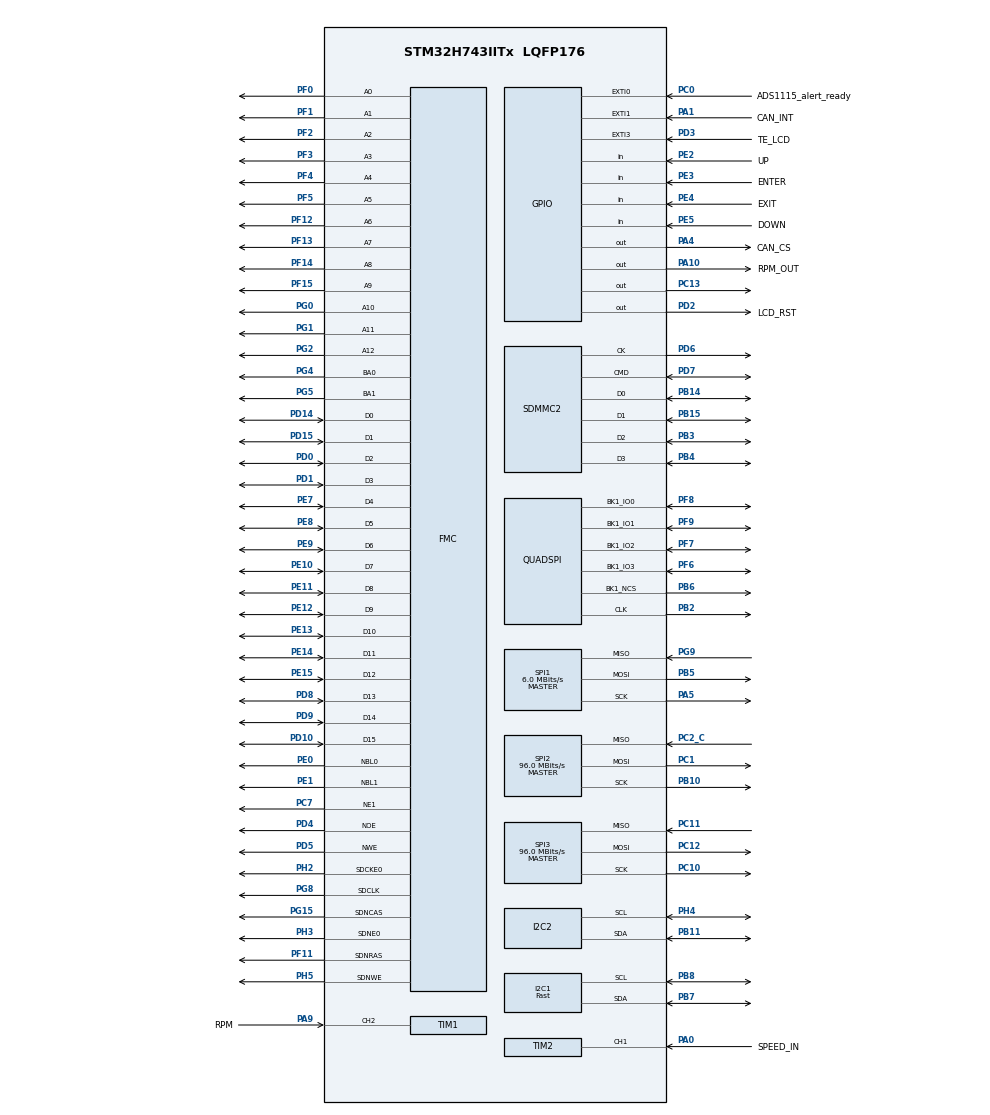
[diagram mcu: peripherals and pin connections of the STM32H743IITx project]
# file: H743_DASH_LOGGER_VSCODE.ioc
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CORTEX_M7.AccessPermission_S-Cortex_Memory_Protection_Unit_Region1_Settings_S=MPU_REGION_FULL_ACCESS
CORTEX_M7.AccessPermission_S-Cortex_Memory_Protection_Unit_Region2_Settings_S=MPU_REGION_FULL_ACCESS
CORTEX_M7.AccessPermission_S-Cortex_Memory_Protection_Unit_Region3_Settings_S=MPU_REGION_FULL_ACCESS
CORTEX_M7.AccessPermission_Spec=MPU_REGION_FULL_ACCESS
CORTEX_M7.BaseAddress_S-Cortex_Memory_Protection_Unit_Region1_Settings_S=0x90000000
CORTEX_M7.BaseAddress_S-Cortex_Memory_Protection_Unit_Region2_Settings_S=0xc0000000
CORTEX_M7.BaseAddress_S-Cortex_Memory_Protection_Unit_Region3_Settings_S=0x90000000
CORTEX_M7.BaseAddress_Spec=0x60000000
CORTEX_M7.CPU_DCache=Enabled
CORTEX_M7.CPU_ICache=Enabled
CORTEX_M7.DisableExec_S-Cortex_Memory_Protection_Unit_Region1_Settings_S=MPU_INSTRUCTION_ACCESS_DISABLE
CORTEX_M7.DisableExec_S-Cortex_Memory_Protection_Unit_Region2_Settings_S=MPU_INSTRUCTION_ACCESS_DISABLE
CORTEX_M7.DisableExec_Spec=MPU_INSTRUCTION_ACCESS_DISABLE
CORTEX_M7.Enable_S-Cortex_Memory_Protection_Unit_Region1_Settings_S=MPU_REGION_ENABLE
CORTEX_M7.Enable_S-Cortex_Memory_Protection_Unit_Region2_Settings_S=MPU_REGION_ENABLE
CORTEX_M7.Enable_S-Cortex_Memory_Protection_Unit_Region3_Settings_S=MPU_REGION_ENABLE
CORTEX_M7.IsBufferable_S-Cortex_Memory_Protection_Unit_Region1_Settings_S=MPU_ACCESS_BUFFERABLE
CORTEX_M7.IsBufferable_S-Cortex_Memory_Protection_Unit_Region2_Settings_S=MPU_ACCESS_NOT_BUFFERABLE
CORTEX_M7.IsBufferable_S-Cortex_Memory_Protection_Unit_Region3_Settings_S=MPU_ACCESS_BUFFERABLE
CORTEX_M7.IsBufferable_Spec=MPU_ACCESS_NOT_BUFFERABLE
CORTEX_M7.IsCacheable_S-Cortex_Memory_Protection_Unit_Region1_Settings_S=MPU_ACCESS_CACHEABLE
CORTEX_M7.IsCacheable_S-Cortex_Memory_Protection_Unit_Region2_Settings_S=MPU_ACCESS_NOT_CACHEABLE
CORTEX_M7.IsCacheable_S-Cortex_Memory_Protection_Unit_Region3_Settings_S=MPU_ACCESS_CACHEABLE
CORTEX_M7.IsCacheable_Spec=MPU_ACCESS_NOT_CACHEABLE
CORTEX_M7.IsShareable_S-Cortex_Memory_Protection_Unit_Region2_Settings_S=MPU_ACCESS_NOT_SHAREABLE
CORTEX_M7.IsShareable_Spec=MPU_ACCESS_NOT_SHAREABLE
CORTEX_M7.MPU_Control=MPU_PRIVILEGED_DEFAULT
CORTEX_M7.Size_S-Cortex_Memory_Protection_Unit_Region1_Settings_S=MPU_REGION_SIZE_16MB
CORTEX_M7.Size_S-Cortex_Memory_Protection_Unit_Region2_Settings_S=MPU_REGION_SIZE_32MB
CORTEX_M7.Size_S-Cortex_Memory_Protection_Unit_Region3_Settings_S=MPU_REGION_SIZE_1MB
CORTEX_M7.Size_Spec=MPU_REGION_SIZE_512KB
CORTEX_M7.SubRegionDisable_S-Cortex_Memory_Protection_Unit_Region2_Settings_S=0x00
CORTEX_M7.SubRegionDisable_Spec=0
CORTEX_M7.TypeExtField_S-Cortex_Memory_Protection_Unit_Region2_Settings_S=MPU_TEX_LEVEL1
CORTEX_M7.TypeExtField_Spec=MPU_TEX_LEVEL0
CORTEX_M7.default_mode_Activation=1
Dma.MEMTOMEM.0.Direction=DMA_MEMORY_TO_MEMORY
Dma.MEMTOMEM.0.EventEnable=DISABLE
Dma.MEMTOMEM.0.FIFOMode=DMA_FIFOMODE_ENABLE
Dma.MEMTOMEM.0.FIFOThreshold=DMA_FIFO_THRESHOLD_FULL
Dma.MEMTOMEM.0.Instance=DMA2_Stream0
Dma.MEMTOMEM.0.MemBurst=DMA_MBURST_SINGLE
Dma.MEMTOMEM.0.MemDataAlignment=DMA_MDATAALIGN_HALFWORD
Dma.MEMTOMEM.0.MemInc=DMA_MINC_DISABLE
Dma.MEMTOMEM.0.Mode=DMA_NORMAL
Dma.MEMTOMEM.0.PeriphBurst=DMA_PBURST_SINGLE
Dma.MEMTOMEM.0.PeriphDataAlignment=DMA_PDATAALIGN_HALFWORD
Dma.MEMTOMEM.0.PeriphInc=DMA_PINC_ENABLE
Dma.MEMTOMEM.0.Polarity=HAL_DMAMUX_REQ_GEN_RISING
Dma.MEMTOMEM.0.Priority=DMA_PRIORITY_HIGH
Dma.MEMTOMEM.0.RequestNumber=1
Dma.MEMTOMEM.0.SignalID=NONE
Dma.MEMTOMEM.0.SyncEnable=DISABLE
Dma.MEMTOMEM.0.SyncPolarity=HAL_DMAMUX_SYNC_NO_EVENT
Dma.MEMTOMEM.0.SyncRequestNumber=1
Dma.MEMTOMEM.0.SyncSignalID=NONE
Dma.Request0=MEMTOMEM
FMC.AddressHoldTime1=8
FMC.AddressSetupTime1=8
FMC.BusTurnAroundDuration1=4
FMC.CASLatency1=FMC_SDRAM_CAS_LATENCY_3
FMC.ColumnBitsNumber1=FMC_SDRAM_COLUMN_BITS_NUM_9
FMC.DataSetupTime1=40
FMC.ExitSelfRefreshDelay1=8
FMC.ExtendedMode1=FMC_EXTENDED_MODE_DISABLE
FMC.LoadToActiveDelay1=3
FMC.RCDDelay1=3
FMC.RPDelay1=3
FMC.RPDelay2=3
FMC.ReadBurst1=FMC_SDRAM_RBURST_DISABLE
FMC.ReadPipeDelay1=FMC_SDRAM_RPIPE_DELAY_1
FMC.ReadPipeDelay2=FMC_SDRAM_RPIPE_DELAY_2
FMC.RowCycleDelay1=8
FMC.RowCycleDelay2=8
FMC.SDClockPeriod1=FMC_SDRAM_CLOCK_PERIOD_3
FMC.SDClockPeriod2=FMC_SDRAM_CLOCK_PERIOD_3
FMC.SelfRefreshTime1=5
FMC.WriteFifo1=FMC_WRITE_FIFO_DISABLE
FMC.WriteRecoveryTime1=4
I2C1.I2C_Speed_Mode=I2C_Fast
I2C1.NoStretchMode=I2C_NOSTRETCH_DISABLE
I2C1.Timing=0x00B03FDB
I2C2.Timing=0x307075B1
Mcu.Family=STM32H7
Mcu.Name=STM32H743IITx
Mcu.Package=LQFP176
Mdma.MDMA_Channel0.Request0=SW
Mdma.MDMA_Channel0.RequestsNb=1
Mdma.MDMA_Channel0.SW.0.BlockCount=0
Mdma.MDMA_Channel0.SW.0.BlockDataLength=0
Mdma.MDMA_Channel0.SW.0.BufferTransferLength=32
Mdma.MDMA_Channel0.SW.0.CircularMode=MDMA_LINEAR_LIST
Mdma.MDMA_Channel0.SW.0.DataAlignment=MDMA_DATAALIGN_RIGHT
Mdma.MDMA_Channel0.SW.0.DestBlockAddressOffset=0
Mdma.MDMA_Channel0.SW.0.DestBurst=MDMA_DEST_BURST_SINGLE
Mdma.MDMA_Channel0.SW.0.DestDataSize=MDMA_DEST_DATASIZE_HALFWORD
Mdma.MDMA_Channel0.SW.0.DestinationInc=MDMA_DEST_INC_DISABLE
Mdma.MDMA_Channel0.SW.0.DstAddress=0
Mdma.MDMA_Channel0.SW.0.Endianness=MDMA_LITTLE_ENDIANNESS_PRESERVE
Mdma.MDMA_Channel0.SW.0.Instance=MDMA_Channel0
Mdma.MDMA_Channel0.SW.0.MaskAddress=0
Mdma.MDMA_Channel0.SW.0.MaskData=0
Mdma.MDMA_Channel0.SW.0.Priority=MDMA_PRIORITY_HIGH
Mdma.MDMA_Channel0.SW.0.Rank=First
Mdma.MDMA_Channel0.SW.0.SourceBlockAddressOffset=0
Mdma.MDMA_Channel0.SW.0.SourceBurst=MDMA_SOURCE_BURST_SINGLE
Mdma.MDMA_Channel0.SW.0.SourceDataSize=MDMA_SRC_DATASIZE_HALFWORD
Mdma.MDMA_Channel0.SW.0.SourceInc=MDMA_SRC_INC_HALFWORD
Mdma.MDMA_Channel0.SW.0.SrcAddress=0
Mdma.MDMA_Channel0.SW.0.TransferTriggerMode=MDMA_BLOCK_TRANSFER
Mdma.RequestSet0=MDMA_Channel0
Mdma.RequestSetsNb=1
NVIC.EXTI0_IRQn=true\:5\:0\:true\:false\:true\:true\:true\:true
NVIC.EXTI1_IRQn=true\:5\:0\:true\:false\:true\:true\:true\:true
NVIC.EXTI3_IRQn=true\:5\:0\:false\:false\:true\:true\:true\:true
NVIC.FMC_IRQn=true\:0\:0\:false\:false\:true\:true\:true\:true
NVIC.I2C1_ER_IRQn=true\:0\:0\:false\:false\:true\:true\:true\:true
NVIC.I2C1_EV_IRQn=true\:0\:0\:false\:false\:true\:true\:true\:true
NVIC.MDMA_IRQn=true\:0\:0\:false\:false\:true\:false\:true\:true
NVIC.PriorityGroup=NVIC_PRIORITYGROUP_4
NVIC.RCC_IRQn=true\:5\:0\:true\:false\:true\:true\:false\:true
NVIC.SDMMC2_IRQn=true\:0\:0\:false\:false\:true\:true\:true\:true
NVIC.TIM1_CC_IRQn=true\:0\:0\:false\:false\:true\:true\:true\:true
NVIC.TIM2_IRQn=true\:0\:0\:false\:false\:true\:true\:true\:true
NVIC.TIM6_DAC_IRQn=true\:5\:0\:true\:false\:true\:true\:true\:true
PA0.GPIO_Label=SPEED_IN
PA0.Signal=S_TIM2_CH1_ETR
PA1.GPIO_Label=CAN_INT
PA1.GPIO_ModeDefaultEXTI=GPIO_MODE_IT_FALLING
PA1.Signal=GPXTI1
PA10.GPIO_Label=RPM_OUT
PA10.Signal=GPIO_Output
PA13\ (JTMS/SWDIO).Mode=Serial_Wire
PA13\ (JTMS/SWDIO).Signal=DEBUG_JTMS-SWDIO
PA14\ (JTCK/SWCLK).Mode=Serial_Wire
PA14\ (JTCK/SWCLK).Signal=DEBUG_JTCK-SWCLK
PA4.GPIO_Label=CAN_CS
PA4.GPIO_Speed=GPIO_SPEED_FREQ_VERY_HIGH
PA4.PinState=GPIO_PIN_SET
PA4.Signal=GPIO_Output
PA5.GPIO_Speed=GPIO_SPEED_FREQ_VERY_HIGH
PA5.Mode=Full_Duplex_Master
PA5.Signal=SPI1_SCK
PA9.GPIO_Label=RPM
PA9.GPIO_PuPd=GPIO_PULLDOWN
PA9.GPIO_Speed=GPIO_SPEED_FREQ_MEDIUM
PA9.Signal=S_TIM1_CH2
PB10.Mode=Full_Duplex_Master
PB10.Signal=SPI2_SCK
PB11.Mode=I2C
PB11.Signal=I2C2_SDA
PB14.Mode=SD_4_bits_Wide_bus
PB14.Signal=SDMMC2_D0
PB15.Mode=SD_4_bits_Wide_bus
PB15.Signal=SDMMC2_D1
PB2.GPIO_Speed=GPIO_SPEED_FREQ_VERY_HIGH
PB2.Mode=Single Bank 1
PB2.Signal=QUADSPI_CLK
PB3\ (JTDO/TRACESWO).Mode=SD_4_bits_Wide_bus
PB3\ (JTDO/TRACESWO).Signal=SDMMC2_D2
PB4\ (NJTRST).Mode=SD_4_bits_Wide_bus
PB4\ (NJTRST).Signal=SDMMC2_D3
PB5.GPIO_Speed=GPIO_SPEED_FREQ_VERY_HIGH
PB5.Mode=Full_Duplex_Master
PB5.Signal=SPI1_MOSI
PB6.GPIO_Speed=GPIO_SPEED_FREQ_VERY_HIGH
PB6.Mode=Single Bank 1
PB6.Signal=QUADSPI_BK1_NCS
PB7.GPIO_Speed=GPIO_SPEED_FREQ_VERY_HIGH
PB7.Mode=I2C
PB7.Signal=I2C1_SDA
PB8.GPIO_Speed=GPIO_SPEED_FREQ_VERY_HIGH
PB8.Mode=I2C
PB8.Signal=I2C1_SCL
PC0.GPIO_Label=ADS1115_alert_ready
PC0.GPIO_ModeDefaultEXTI=GPIO_MODE_IT_FALLING
PC0.GPIO_PuPd=GPIO_PULLUP
PC0.Signal=GPXTI0
PC1.Mode=Full_Duplex_Master
PC1.Signal=SPI2_MOSI
PC10.Mode=Full_Duplex_Master
PC10.Signal=SPI3_SCK
PC11.Mode=Full_Duplex_Master
PC11.Signal=SPI3_MISO
PC12.Mode=Full_Duplex_Master
PC12.Signal=SPI3_MOSI
PC13.Signal=GPIO_Output
PC14-OSC32_IN\ (OSC32_IN).Mode=LSE-External-Oscillator
PC14-OSC32_IN\ (OSC32_IN).Signal=RCC_OSC32_IN
PC15-OSC32_OUT\ (OSC32_OUT).Mode=LSE-External-Oscillator
PC15-OSC32_OUT\ (OSC32_OUT).Signal=RCC_OSC32_OUT
PC2_C.Mode=Full_Duplex_Master
PC2_C.Signal=SPI2_MISO
PC7.GPIO_Speed_High_Default=GPIO_SPEED_FREQ_VERY_HIGH
PC7.Mode=NorPsramChipSelect1_1
PC7.Signal=FMC_NE1
PD0.GPIO_Speed_High_Default=GPIO_SPEED_FREQ_VERY_HIGH
PD0.Signal=FMC_D2_DA2
PD1.GPIO_Speed_High_Default=GPIO_SPEED_FREQ_VERY_HIGH
PD1.Signal=FMC_D3_DA3
PD10.GPIO_Speed_High_Default=GPIO_SPEED_FREQ_VERY_HIGH
PD10.Signal=FMC_D15_DA15
PD14.GPIO_Speed_High_Default=GPIO_SPEED_FREQ_VERY_HIGH
PD14.Signal=FMC_D0_DA0
PD15.GPIO_Speed_High_Default=GPIO_SPEED_FREQ_VERY_HIGH
PD15.Signal=FMC_D1_DA1
PD2.GPIO_Label=LCD_RST
PD2.GPIO_Speed=GPIO_SPEED_FREQ_VERY_HIGH
PD2.Signal=GPIO_Output
PD3.GPIO_Label=TE_LCD
PD3.GPIO_ModeDefaultEXTI=GPIO_MODE_IT_RISING
PD3.GPIO_PuPd=GPIO_PULLDOWN
PD3.Signal=GPXTI3
PD4.GPIO_Speed_High_Default=GPIO_SPEED_FREQ_VERY_HIGH
PD4.Signal=FMC_NOE
PD5.GPIO_Speed_High_Default=GPIO_SPEED_FREQ_VERY_HIGH
PD5.Signal=FMC_NWE
PD6.Mode=SD_4_bits_Wide_bus
PD6.Signal=SDMMC2_CK
PD7.Mode=SD_4_bits_Wide_bus
PD7.Signal=SDMMC2_CMD
PD8.GPIO_Speed_High_Default=GPIO_SPEED_FREQ_VERY_HIGH
PD8.Signal=FMC_D13_DA13
PD9.GPIO_Speed_High_Default=GPIO_SPEED_FREQ_VERY_HIGH
PD9.Signal=FMC_D14_DA14
PE0.GPIO_Speed_High_Default=GPIO_SPEED_FREQ_VERY_HIGH
PE0.Signal=FMC_NBL0
PE1.GPIO_Speed_High_Default=GPIO_SPEED_FREQ_VERY_HIGH
PE1.Signal=FMC_NBL1
PE10.GPIO_Speed_High_Default=GPIO_SPEED_FREQ_VERY_HIGH
PE10.Signal=FMC_D7_DA7
PE11.GPIO_Speed_High_Default=GPIO_SPEED_FREQ_VERY_HIGH
PE11.Signal=FMC_D8_DA8
PE12.GPIO_Speed_High_Default=GPIO_SPEED_FREQ_VERY_HIGH
PE12.Signal=FMC_D9_DA9
PE13.GPIO_Speed_High_Default=GPIO_SPEED_FREQ_VERY_HIGH
PE13.Signal=FMC_D10_DA10
PE14.GPIO_Speed_High_Default=GPIO_SPEED_FREQ_VERY_HIGH
PE14.Signal=FMC_D11_DA11
PE15.GPIO_Speed_High_Default=GPIO_SPEED_FREQ_VERY_HIGH
PE15.Signal=FMC_D12_DA12
PE2.GPIO_Label=UP
PE2.GPIO_Mode=GPIO_MODE_INPUT
PE2.GPIO_PuPd=GPIO_PULLUP
PE2.Signal=GPIO_Input
PE3.GPIO_Label=ENTER
PE3.GPIO_Mode=GPIO_MODE_INPUT
PE3.GPIO_PuPd=GPIO_PULLUP
PE3.Signal=GPIO_Input
PE4.GPIO_Label=EXIT
PE4.GPIO_Mode=GPIO_MODE_INPUT
PE4.GPIO_PuPd=GPIO_PULLUP
PE4.Signal=GPIO_Input
PE5.GPIO_Label=DOWN
PE5.GPIO_Mode=GPIO_MODE_INPUT
PE5.GPIO_PuPd=GPIO_PULLUP
PE5.Signal=GPIO_Input
PE7.GPIO_Speed_High_Default=GPIO_SPEED_FREQ_VERY_HIGH
PE7.Signal=FMC_D4_DA4
PE8.GPIO_Speed_High_Default=GPIO_SPEED_FREQ_VERY_HIGH
PE8.Signal=FMC_D5_DA5
PE9.GPIO_Speed_High_Default=GPIO_SPEED_FREQ_VERY_HIGH
PE9.Signal=FMC_D6_DA6
PF0.GPIO_Speed_High_Default=GPIO_SPEED_FREQ_VERY_HIGH
PF0.Signal=FMC_A0
PF1.GPIO_Speed_High_Default=GPIO_SPEED_FREQ_VERY_HIGH
PF1.Signal=FMC_A1
PF11.GPIO_Speed_High_Default=GPIO_SPEED_FREQ_VERY_HIGH
PF11.Signal=FMC_SDNRAS
PF12.GPIO_Speed_High_Default=GPIO_SPEED_FREQ_VERY_HIGH
PF12.Signal=FMC_A6
PF13.GPIO_Speed_High_Default=GPIO_SPEED_FREQ_VERY_HIGH
PF13.Signal=FMC_A7
PF14.GPIO_Speed_High_Default=GPIO_SPEED_FREQ_VERY_HIGH
PF14.Signal=FMC_A8
PF15.GPIO_Speed_High_Default=GPIO_SPEED_FREQ_VERY_HIGH
PF15.Signal=FMC_A9
PF2.GPIO_Speed_High_Default=GPIO_SPEED_FREQ_VERY_HIGH
PF2.Signal=FMC_A2
PF3.GPIO_Speed_High_Default=GPIO_SPEED_FREQ_VERY_HIGH
PF3.Signal=FMC_A3
PF4.GPIO_Speed_High_Default=GPIO_SPEED_FREQ_VERY_HIGH
PF4.Signal=FMC_A4
PF5.GPIO_Speed_High_Default=GPIO_SPEED_FREQ_VERY_HIGH
PF5.Signal=FMC_A5
PF6.GPIO_Speed=GPIO_SPEED_FREQ_VERY_HIGH
PF6.Mode=Single Bank 1
PF6.Signal=QUADSPI_BK1_IO3
PF7.GPIO_Speed=GPIO_SPEED_FREQ_VERY_HIGH
PF7.Mode=Single Bank 1
PF7.Signal=QUADSPI_BK1_IO2
PF8.GPIO_Speed=GPIO_SPEED_FREQ_VERY_HIGH
PF8.Mode=Single Bank 1
PF8.Signal=QUADSPI_BK1_IO0
PF9.GPIO_Speed=GPIO_SPEED_FREQ_VERY_HIGH
PF9.Mode=Single Bank 1
PF9.Signal=QUADSPI_BK1_IO1
PG0.GPIO_Speed_High_Default=GPIO_SPEED_FREQ_VERY_HIGH
PG0.Signal=FMC_A10
PG1.GPIO_Speed_High_Default=GPIO_SPEED_FREQ_VERY_HIGH
PG1.Signal=FMC_A11
PG15.GPIO_Speed_High_Default=GPIO_SPEED_FREQ_VERY_HIGH
PG15.Signal=FMC_SDNCAS
PG2.GPIO_Speed_High_Default=GPIO_SPEED_FREQ_VERY_HIGH
PG2.Signal=FMC_A12
PG4.GPIO_Speed_High_Default=GPIO_SPEED_FREQ_VERY_HIGH
PG4.Signal=FMC_A14_BA0
PG5.GPIO_Speed_High_Default=GPIO_SPEED_FREQ_VERY_HIGH
PG5.Signal=FMC_A15_BA1
PG8.GPIO_Speed_High_Default=GPIO_SPEED_FREQ_VERY_HIGH
PG8.Signal=FMC_SDCLK
PG9.GPIO_Speed=GPIO_SPEED_FREQ_VERY_HIGH
PG9.Mode=Full_Duplex_Master
PG9.Signal=SPI1_MISO
PH0-OSC_IN\ (PH0).Mode=HSE-External-Oscillator
PH0-OSC_IN\ (PH0).Signal=RCC_OSC_IN
PH1-OSC_OUT\ (PH1).Mode=HSE-External-Oscillator
PH1-OSC_OUT\ (PH1).Signal=RCC_OSC_OUT
PH2.GPIO_Speed_High_Default=GPIO_SPEED_FREQ_VERY_HIGH
PH2.Mode=SdramChipSelect1_1
PH2.Signal=FMC_SDCKE0
PH3.GPIO_Speed_High_Default=GPIO_SPEED_FREQ_VERY_HIGH
PH3.Mode=SdramChipSelect1_1
PH3.Signal=FMC_SDNE0
PH4.Mode=I2C
PH4.Signal=I2C2_SCL
PH5.GPIO_Speed_High_Default=GPIO_SPEED_FREQ_VERY_HIGH
PH5.Signal=FMC_SDNWE
ProjectManager.HeapSize=0x200
ProjectManager.StackSize=0x400
ProjectManager.TargetToolchain=CMake
QUADSPI.ChipSelectHighTime=QSPI_CS_HIGH_TIME_2_CYCLE
QUADSPI.ClockPrescaler=2
QUADSPI.FifoThreshold=1
QUADSPI.FlashSize=23
QUADSPI.SampleShifting=QSPI_SAMPLE_SHIFTING_HALFCYCLE
RCC.ADCFreq_Value=56000000
RCC.APB1Freq_Value=120000000
RCC.APB2Freq_Value=120000000
RCC.APB3Freq_Value=120000000
RCC.APB4Freq_Value=120000000
RCC.CortexFreq_Value=480000000
RCC.D1PPRE=RCC_APB3_DIV2
RCC.D2PPRE1=RCC_APB1_DIV2
RCC.D2PPRE2=RCC_APB2_DIV2
RCC.D3PPRE=RCC_APB4_DIV2
RCC.DIVM1=4
RCC.DIVM2=4
RCC.DIVN1=60
RCC.DIVN2=14
RCC.DIVP2=4
RCC.DIVQ1=5
RCC.DIVQ2=4
RCC.FMCCLockSelection=RCC_FMCCLKSOURCE_PLL2
RCC.HCLKFreq_Value=240000000
RCC.HPRE=RCC_HCLK_DIV2
RCC.PLL2FRACN=0
RCC.PLL3FRACN=0
RCC.PLLFRACN=0
RCC.ProductRev=revV
RCC.SYSCLKFreq_VALUE=480000000
RCC.SYSCLKSource=RCC_SYSCLKSOURCE_PLLCLK
RCC.SupplySource=PWR_LDO_SUPPLY
RCC.USART16CLockSelection=RCC_USART16CLKSOURCE_HSI
RCC.USBFreq_Value=192000000
SDMMC2.ClockDiv=23
SH.FMC_A0.0=FMC_A0,A0_1
SH.FMC_A0.1=FMC_A0,13b-sda1
SH.FMC_A1.0=FMC_A1,13b-sda1
SH.FMC_A10.0=FMC_A10,13b-sda1
SH.FMC_A11.0=FMC_A11,13b-sda1
SH.FMC_A12.0=FMC_A12,13b-sda1
SH.FMC_A14_BA0.0=FMC_BA0,FourSdramBanks1
SH.FMC_A15_BA1.0=FMC_BA1,FourSdramBanks1
SH.FMC_A2.0=FMC_A2,13b-sda1
SH.FMC_A3.0=FMC_A3,13b-sda1
SH.FMC_A4.0=FMC_A4,13b-sda1
SH.FMC_A5.0=FMC_A5,13b-sda1
SH.FMC_A6.0=FMC_A6,13b-sda1
SH.FMC_A7.0=FMC_A7,13b-sda1
SH.FMC_A8.0=FMC_A8,13b-sda1
SH.FMC_A9.0=FMC_A9,13b-sda1
SH.FMC_D0_DA0.0=FMC_D0,16b-d1
SH.FMC_D0_DA0.1=FMC_D0,sd-16b-d1
SH.FMC_D10_DA10.0=FMC_D10,16b-d1
SH.FMC_D10_DA10.1=FMC_D10,sd-16b-d1
SH.FMC_D11_DA11.0=FMC_D11,16b-d1
SH.FMC_D11_DA11.1=FMC_D11,sd-16b-d1
SH.FMC_D12_DA12.0=FMC_D12,16b-d1
SH.FMC_D12_DA12.1=FMC_D12,sd-16b-d1
SH.FMC_D13_DA13.0=FMC_D13,16b-d1
SH.FMC_D13_DA13.1=FMC_D13,sd-16b-d1
SH.FMC_D14_DA14.0=FMC_D14,16b-d1
SH.FMC_D14_DA14.1=FMC_D14,sd-16b-d1
SH.FMC_D15_DA15.0=FMC_D15,16b-d1
SH.FMC_D15_DA15.1=FMC_D15,sd-16b-d1
SH.FMC_D1_DA1.0=FMC_D1,16b-d1
SH.FMC_D1_DA1.1=FMC_D1,sd-16b-d1
SH.FMC_D2_DA2.0=FMC_D2,16b-d1
SH.FMC_D2_DA2.1=FMC_D2,sd-16b-d1
SH.FMC_D3_DA3.0=FMC_D3,16b-d1
SH.FMC_D3_DA3.1=FMC_D3,sd-16b-d1
SH.FMC_D4_DA4.0=FMC_D4,16b-d1
SH.FMC_D4_DA4.1=FMC_D4,sd-16b-d1
SH.FMC_D5_DA5.0=FMC_D5,16b-d1
SH.FMC_D5_DA5.1=FMC_D5,sd-16b-d1
SH.FMC_D6_DA6.0=FMC_D6,16b-d1
SH.FMC_D6_DA6.1=FMC_D6,sd-16b-d1
SH.FMC_D7_DA7.0=FMC_D7,16b-d1
SH.FMC_D7_DA7.1=FMC_D7,sd-16b-d1
SH.FMC_D8_DA8.0=FMC_D8,16b-d1
SH.FMC_D8_DA8.1=FMC_D8,sd-16b-d1
SH.FMC_D9_DA9.0=FMC_D9,16b-d1
SH.FMC_D9_DA9.1=FMC_D9,sd-16b-d1
SH.FMC_NBL0.0=FMC_NBL0,Sd2ByteEnable1
SH.FMC_NBL1.0=FMC_NBL1,Sd2ByteEnable1
SH.FMC_NOE.0=FMC_NOE,Lcd1
SH.FMC_NWE.0=FMC_NWE,Lcd1
SH.FMC_SDCLK.0=FMC_SDCLK,13b-sda1
SH.FMC_SDNCAS.0=FMC_SDNCAS,13b-sda1
SH.FMC_SDNRAS.0=FMC_SDNRAS,13b-sda1
SH.FMC_SDNWE.0=FMC_SDNWE,13b-sda1
SH.S_TIM1_CH2.0=TIM1_CH2,PWM_Input_2
SH.S_TIM2_CH1_ETR.0=TIM2_CH1,PWM_Input_1
SPI1.BaudRatePrescaler=SPI_BAUDRATEPRESCALER_32
SPI1.CalculateBaudRate=6.0 MBits/s
SPI1.DataSize=SPI_DATASIZE_8BIT
SPI1.Direction=SPI_DIRECTION_2LINES
SPI1.FirstBit=SPI_FIRSTBIT_MSB
SPI1.Mode=SPI_MODE_MASTER
SPI1.NSSPMode=SPI_NSS_PULSE_DISABLE
SPI1.VirtualType=VM_MASTER
SPI2.CalculateBaudRate=96.0 MBits/s
SPI2.Direction=SPI_DIRECTION_2LINES
SPI2.Mode=SPI_MODE_MASTER
SPI2.VirtualType=VM_MASTER
SPI3.CalculateBaudRate=96.0 MBits/s
SPI3.Direction=SPI_DIRECTION_2LINES
SPI3.Mode=SPI_MODE_MASTER
SPI3.VirtualType=VM_MASTER
TIM1.ICFilter_1=8
TIM1.ICFilter_2=8
TIM1.ICPolarity_1=TIM_INPUTCHANNELPOLARITY_FALLING
TIM1.Prescaler=999
TIM2.ICFilter_1=8
TIM2.ICFilter_2=8
TIM2.ICPolarity_1=TIM_INPUTCHANNELPOLARITY_RISING
TIM2.Prescaler=999
TIM6.Period=4999
TIM6.Prescaler=239
VP_CRC_VS_CRC.Mode=CRC_Activate
VP_FATFS_VS_SDIO.Mode=SDIO
VP_MEMORYMAP_VS_MEMORYMAP.Mode=CurAppReg
VP_RNG_VS_RNG.Mode=RNG_Activate
VP_TIM1_VS_ClockSourceINT.Mode=Internal
VP_TIM2_VS_ClockSourceINT.Mode=Internal
VP_TIM6_VS_ClockSourceINT.Mode=Enable_Timer
board=custom

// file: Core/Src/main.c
/* USER CODE BEGIN Header */
/**
  ******************************************************************************
  * @file           : main.c
  * @brief          : Main program body
  ******************************************************************************
  * @attention
  *
  * Copyright (c) 2026 STMicroelectronics.
  * All rights reserved.
  *
  * This software is licensed under terms that can be found in the LICENSE file
  * in the root directory of this software component.
  * If no LICENSE file comes with this software, it is provided AS-IS.
  *
  ******************************************************************************
  */
/* USER CODE END Header */
#include "main.h"
#include "crc.h"
#include "dma.h"
#include "fatfs.h"
#include "i2c.h"
#include "mdma.h"
#include "quadspi.h"
#include "rng.h"
#include "sdmmc.h"
#include "spi.h"
#include "tim.h"
#include "gpio.h"
#include "fmc.h"

/* USER CODE BEGIN Includes */
#include "INCLUDES.hpp"
/* USER CODE END Includes */

/* USER CODE BEGIN PTD */

//const uint8_t __attribute__ ((section(".extFlashMem"))) data[]="helo world!";

volatile uint8_t qspi_test_value;

/* USER CODE END PTD */

/* USER CODE BEGIN PD */

void setup(void);
void tasks(void);

/* USER CODE END PD */

/* USER CODE BEGIN PV */

volatile uint32_t startup_init_stage = 0U;
volatile uint32_t startup_error_stage = 0U;
volatile uint32_t startup_error_return_address = 0U;
volatile uint32_t startup_error_exception = 0U;

void setup();
void tasks();
uint32_t non_blocking_task(uint32_t last_tick, const uint32_t delay_interval) ;
/* USER CODE END PV */

void SystemClock_Config(void);
static void MPU_Config(void);
/* USER CODE BEGIN PFP */

//#ifdef __GNUC__
//#define PUTCHAR_PROTOTYPE int __io_putchar(int ch)
//#else
//#define PUTCHAR_PROTOTYPE int fputc(int ch, FILE *f)
//#endif
//PUTCHAR_PROTOTYPE
//{
//    HAL_UART_Transmit(&huart1 , (uint8_t *)&ch, 1, 0xFFFF);
//    return ch;
//}

static void ReadFlashData(void)
{
	 const volatile uint8_t *flash =
	        (const volatile uint8_t *)0x90000000U;

	    qspi_test_value = flash[0x100U];
}

/* USER CODE END PFP */

int main(void)
{

  /* USER CODE BEGIN 1 */

  startup_init_stage = 1U;

  /* USER CODE END 1 */

  /* MPU Configuration--------------------------------------------------------*/
  MPU_Config();

  /* Enable the CPU Cache */

  /* Enable I-Cache---------------------------------------------------------*/
  SCB_EnableICache();

  /* Enable D-Cache---------------------------------------------------------*/
  SCB_EnableDCache();

  /* MCU Configuration--------------------------------------------------------*/

  /* Reset of all peripherals, Initializes the Flash interface and the Systick. */
  HAL_Init();

  /* USER CODE BEGIN Init */
  /* Debug only: make buffered-write BusFaults precise. */

  /* USER CODE END Init */

  /* Configure the system clock */
  SystemClock_Config();

  /* Initialize all configured peripherals */
  MX_GPIO_Init();
  MX_DMA_Init();
  MX_MDMA_Init();
  MX_FMC_Init();
  MX_CRC_Init();
  MX_TIM1_Init();
  MX_QUADSPI_Init();
  MX_TIM6_Init();
  MX_I2C1_Init();
  MX_SPI1_Init();
  MX_RNG_Init();
  MX_I2C2_Init();
  MX_SPI2_Init();
  MX_SPI3_Init();
  MX_TIM2_Init();
  MX_SDMMC2_SD_Init();
  MX_FATFS_Init();
  /* USER CODE BEGIN 2 */
  startup_init_stage = 30U;
  setup();
  startup_init_stage = 31U;

  /* USER CODE END 2 */

  /* Infinite loop */
  while (1)
  {

    /* USER CODE BEGIN 3 */
    /* Run all LVGL timers, animations, rendering and display refreshes. */
	  tasks();

    /*
     * This prevents a useless 100% busy loop while retaining a responsive
     * 1 ms service cadence for LVGL and the display driver.
     */

  }
  /* USER CODE END 3 */
}

void SystemClock_Config(void)
{
  RCC_OscInitTypeDef RCC_OscInitStruct = {0};
  RCC_ClkInitTypeDef RCC_ClkInitStruct = {0};

  /** Supply configuration update enable
  */
  HAL_PWREx_ConfigSupply(PWR_LDO_SUPPLY);

  /** Configure the main internal regulator output voltage
  */
  __HAL_PWR_VOLTAGESCALING_CONFIG(PWR_REGULATOR_VOLTAGE_SCALE0);

  while(!__HAL_PWR_GET_FLAG(PWR_FLAG_VOSRDY)) {}

  /** Initializes the RCC Oscillators according to the specified parameters
  * in the RCC_OscInitTypeDef structure.
  */
  RCC_OscInitStruct.OscillatorType = RCC_OSCILLATORTYPE_HSI48|RCC_OSCILLATORTYPE_HSI;
  RCC_OscInitStruct.HSIState = RCC_HSI_DIV1;
  RCC_OscInitStruct.HSICalibrationValue = RCC_HSICALIBRATION_DEFAULT;
  RCC_OscInitStruct.HSI48State = RCC_HSI48_ON;
  RCC_OscInitStruct.PLL.PLLState = RCC_PLL_ON;
  RCC_OscInitStruct.PLL.PLLSource = RCC_PLLSOURCE_HSI;
  RCC_OscInitStruct.PLL.PLLM = 4;
  RCC_OscInitStruct.PLL.PLLN = 60;
  RCC_OscInitStruct.PLL.PLLP = 2;
  RCC_OscInitStruct.PLL.PLLQ = 5;
  RCC_OscInitStruct.PLL.PLLR = 2;
  RCC_OscInitStruct.PLL.PLLRGE = RCC_PLL1VCIRANGE_3;
  RCC_OscInitStruct.PLL.PLLVCOSEL = RCC_PLL1VCOWIDE;
  RCC_OscInitStruct.PLL.PLLFRACN = 0;
  if (HAL_RCC_OscConfig(&RCC_OscInitStruct) != HAL_OK)
  {
    Error_Handler();
  }

  /** Initializes the CPU, AHB and APB buses clocks
  */
  RCC_ClkInitStruct.ClockType = RCC_CLOCKTYPE_HCLK|RCC_CLOCKTYPE_SYSCLK
                              |RCC_CLOCKTYPE_PCLK1|RCC_CLOCKTYPE_PCLK2
                              |RCC_CLOCKTYPE_D3PCLK1|RCC_CLOCKTYPE_D1PCLK1;
  RCC_ClkInitStruct.SYSCLKSource = RCC_SYSCLKSOURCE_PLLCLK;
  RCC_ClkInitStruct.SYSCLKDivider = RCC_SYSCLK_DIV1;
  RCC_ClkInitStruct.AHBCLKDivider = RCC_HCLK_DIV2;
  RCC_ClkInitStruct.APB3CLKDivider = RCC_APB3_DIV2;
  RCC_ClkInitStruct.APB1CLKDivider = RCC_APB1_DIV2;
  RCC_ClkInitStruct.APB2CLKDivider = RCC_APB2_DIV2;
  RCC_ClkInitStruct.APB4CLKDivider = RCC_APB4_DIV2;

  if (HAL_RCC_ClockConfig(&RCC_ClkInitStruct, FLASH_LATENCY_4) != HAL_OK)
  {
    Error_Handler();
  }
}

 /* MPU Configuration */

void MPU_Config(void)
{
  MPU_Region_InitTypeDef MPU_InitStruct = {0};

  /* Disables the MPU */
  HAL_MPU_Disable();

  /** Initializes and configures the Region and the memory to be protected
  */
  MPU_InitStruct.Enable = MPU_REGION_ENABLE;
  MPU_InitStruct.Number = MPU_REGION_NUMBER0;
  MPU_InitStruct.BaseAddress = 0x60000000;
  MPU_InitStruct.Size = MPU_REGION_SIZE_512KB;
  MPU_InitStruct.SubRegionDisable = 0;
  MPU_InitStruct.TypeExtField = MPU_TEX_LEVEL0;
  MPU_InitStruct.AccessPermission = MPU_REGION_FULL_ACCESS;
  MPU_InitStruct.DisableExec = MPU_INSTRUCTION_ACCESS_DISABLE;
  MPU_InitStruct.IsShareable = MPU_ACCESS_NOT_SHAREABLE;
  MPU_InitStruct.IsCacheable = MPU_ACCESS_NOT_CACHEABLE;
  MPU_InitStruct.IsBufferable = MPU_ACCESS_NOT_BUFFERABLE;

  HAL_MPU_ConfigRegion(&MPU_InitStruct);

  /** Initializes and configures the Region and the memory to be protected
  */
  MPU_InitStruct.Number = MPU_REGION_NUMBER1;
  MPU_InitStruct.BaseAddress = 0x90000000;
  MPU_InitStruct.Size = MPU_REGION_SIZE_16MB;
  MPU_InitStruct.SubRegionDisable = 0x0;
  MPU_InitStruct.IsCacheable = MPU_ACCESS_CACHEABLE;
  MPU_InitStruct.IsBufferable = MPU_ACCESS_BUFFERABLE;

  HAL_MPU_ConfigRegion(&MPU_InitStruct);

  /** Initializes and configures the Region and the memory to be protected
  */
  MPU_InitStruct.Number = MPU_REGION_NUMBER2;
  MPU_InitStruct.BaseAddress = 0xc0000000;
  MPU_InitStruct.Size = MPU_REGION_SIZE_32MB;
  MPU_InitStruct.SubRegionDisable = 0x00;
  MPU_InitStruct.TypeExtField = MPU_TEX_LEVEL1;
  MPU_InitStruct.IsCacheable = MPU_ACCESS_NOT_CACHEABLE;
  MPU_InitStruct.IsBufferable = MPU_ACCESS_NOT_BUFFERABLE;

  HAL_MPU_ConfigRegion(&MPU_InitStruct);

  /** Initializes and configures the Region and the memory to be protected
  */
  MPU_InitStruct.Number = MPU_REGION_NUMBER3;
  MPU_InitStruct.BaseAddress = 0x90000000;
  MPU_InitStruct.Size = MPU_REGION_SIZE_1MB;
  MPU_InitStruct.SubRegionDisable = 0x0;
  MPU_InitStruct.TypeExtField = MPU_TEX_LEVEL0;
  MPU_InitStruct.DisableExec = MPU_INSTRUCTION_ACCESS_ENABLE;
  MPU_InitStruct.IsCacheable = MPU_ACCESS_CACHEABLE;
  MPU_InitStruct.IsBufferable = MPU_ACCESS_BUFFERABLE;

  HAL_MPU_ConfigRegion(&MPU_InitStruct);
  /* Enables the MPU */
  HAL_MPU_Enable(MPU_PRIVILEGED_DEFAULT);

}

void Error_Handler(void)
{
  /* USER CODE BEGIN Error_Handler_Debug */
  /* User can add his own implementation to report the HAL error return state */
  startup_error_stage = startup_init_stage;
  startup_error_return_address =
      ((uint32_t)__builtin_return_address(0)) & 0xFFFFFFFEU;
  startup_error_exception = __get_IPSR();
  __disable_irq();
  while (1)
  {
  }
  /* USER CODE END Error_Handler_Debug */
}
